# EOS-S3 register map
File version: 0.1
CPU: CM4 r0p1, selectable endian, MPU, FPU, 3 interrupt priority bits
Registers are 32-bit, read-write, reset 0x0 unless marked. A register's access mark holds for its fields unless they carry their own. Offsets are from the block's base; [hi:lo] are bit positions; {n}, {i} and the like mark numbered series; 'fields as' and 'values as' point back to an identical list.

## CRU — Clock Reset Unit
Base 0x40004000
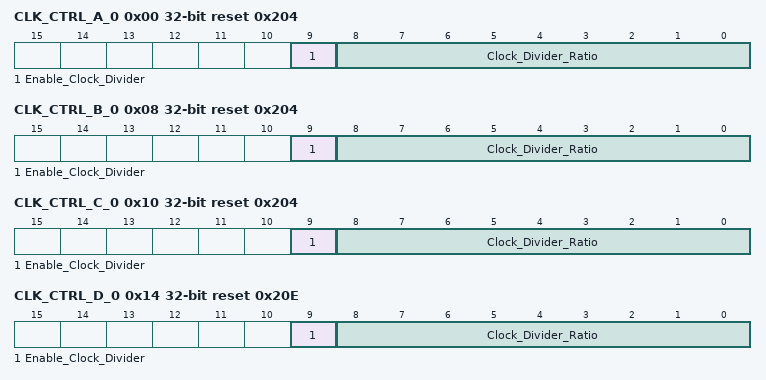
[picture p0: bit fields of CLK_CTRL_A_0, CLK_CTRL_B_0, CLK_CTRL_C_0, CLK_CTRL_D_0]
0x00 CLK_CTRL_A_0 reset 0x204 — For Clock 10 (SYNC Up on A0 and AHB Interface of Batching Memory, AUDIO DMA, M4 SRAMs,M4 Bus Matrix and Trace block)
  [9] Enable_Clock_Divider — Control if the clock divider is on
  [8:0] Clock_Divider_Ratio range 0..510 — High Speed Clock Divider Ratio. Ratio equals value in register + 2. default div is 6
0x04 CLK_CTRL_A_1 — For Clock 10 (SYNC Up on A0 and AHB Interface of Batching Memory, AUDIO DMA, M4 SRAMs,M4 Bus Matrix and Trace block)
  [1:0] Clock_Source_Selection — Select the clock source
    0=with_hs_clk (Selects the High speed/Divided clock); 1=with_32khz_clk (Selects the 32KHz oscillator)
0x08 CLK_CTRL_B_0 reset 0x204 — For Clock 2 (FB, A1 (Including CFGSM))
  fields as CLK_CTRL_A_0
0x0C CLK_CTRL_B_1 — For Clock 2 (FB, A1 (Including CFGSM))
  fields as CLK_CTRL_A_1
0x10 CLK_CTRL_C_0 reset 0x204 — For Clock 8 X4 (FFE X4 clk)
  fields as CLK_CTRL_A_0
0x14 CLK_CTRL_D_0 reset 0x20E — For Clock 11 (To M4 peripherals - AHB/APB bridge, UART, WDT and TIMER)
  [9] Enable_Clock_Divider — Control if the clock divider is on
  [8:0] Clock_Divider_Ratio range 0..510 — High Speed Clock Divider Ratio. Ratio equals value in register + 2, default div is 16
0x18 CLK_CTRL_E_0 — For Clock 12 - Reserved
0x1C CLK_CTRL_E_1 ro — For Clock 12
  [1:0] Clock_Source_Selection — The selected the clock source
    values as CLK_CTRL_A_1.Clock_Source_Selection
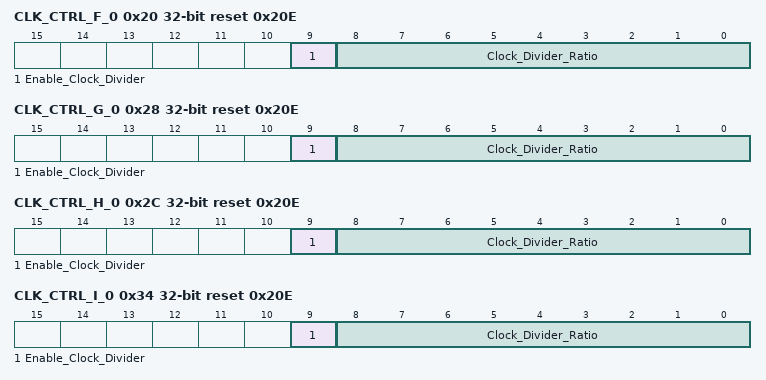
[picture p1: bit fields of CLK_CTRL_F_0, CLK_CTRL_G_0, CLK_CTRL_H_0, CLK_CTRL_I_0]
0x20 CLK_CTRL_F_0 reset 0x20E — For Clock 16 (FB)
  fields as CLK_CTRL_D_0
0x24 CLK_CTRL_F_1 — For Clock 16 (FB)
  fields as CLK_CTRL_A_1
0x28 CLK_CTRL_G_0 reset 0x20E — For Clock 30 (PDM LEFT/RIGHT clk, I2S Master clk)
  [9] Enable_Clock_Divider — Control if the clock divider is on
  [8:0] Clock_Divider_Ratio range 0..510 — High Speed Clock Divider Ratio. Ratio equals value in register + 2, default div is 32
0x2C CLK_CTRL_H_0 reset 0x20E — For Clock 19 (ADC)
  fields as CLK_CTRL_D_0
0x30 CLK_CTRL_H_1 ro — For Clock 19 (ADC)
  fields as CLK_CTRL_A_1
0x34 CLK_CTRL_I_0 reset 0x20E — For Clock 21 (FB - additional clk)
  fields as CLK_CTRL_D_0
0x38 CLK_CTRL_I_1 — For Clock 21 (FB - additional clk)
  fields as CLK_CTRL_A_1
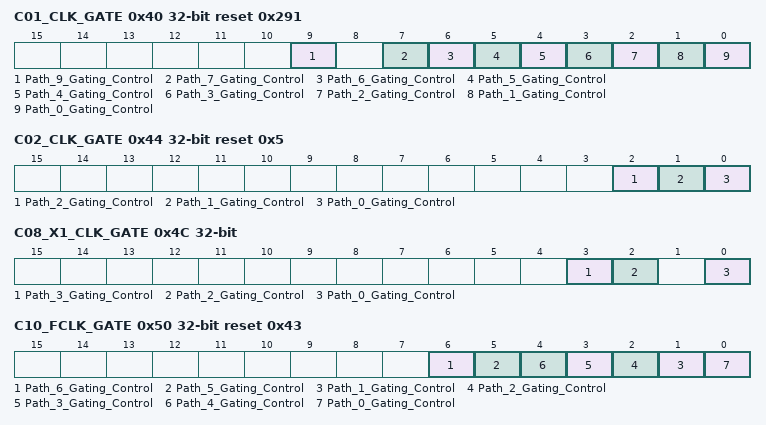
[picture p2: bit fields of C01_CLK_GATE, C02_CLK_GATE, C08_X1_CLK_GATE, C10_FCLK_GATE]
0x40 C01_CLK_GATE reset 0x291 — Gating control for Clock 1
  [all] fields
    0=stop (Clock is stop); 1=run (Clock is runnig)
  [9] Path_9_Gating_Control — For SPT
  [7] Path_7_Gating_Control — Not specified
  [6] Path_6_Gating_Control — To SDMA
  [5] Path_5_Gating_Control — To I2S module inside A1
  [4] Path_4_Gating_Control — To AHB2APB Bridge /CFG DMA Bridge inside A1 , Allow M4 to configure SPI Master to load the code
  [3] Path_3_Gating_Control — To FFE
  [2] Path_2_Gating_Control — To packet FIFO
  [1] Path_1_Gating_Control — To SDMA SRAM
  [0] Path_0_Gating_Control ro — To A0
0x44 C02_CLK_GATE reset 0x5 — Gating control for Clock 2
  [all] fields
    0=stop (Clock is stop); 1=run (Clock is runnig)
  [2] Path_2_Gating_Control — Not specified
  [1] Path_1_Gating_Control — To FB
  [0] Path_0_Gating_Control — To A1 (including CFGSM)
0x48 C08_X4_CLK_GATE — Gating control for FFE X4 clock
  [0] Path_0_Gating_Control — To FFE X4 clk
    0=stop (Clock is stop); 1=run (Clock is runnig)
0x4C C08_X1_CLK_GATE (reset mask 0x7) — Gating control for FFE X1 clock
  [all] fields
    0=stop (Clock is stop); 1=run (Clock is runnig)
  [3] Path_3_Gating_Control — To To PF ASYNC FIFO 0
  [2] Path_2_Gating_Control — To To A0
  [0] Path_0_Gating_Control — To FFE X1 clk
0x50 C10_FCLK_GATE reset 0x43 — Gating control for Clock 10
  [all] fields
    0=stop (Clock is stop); 1=run (Clock is runnig)
  [6] Path_6_Gating_Control — To the SYNC Up on A0 and AHB Interface of Batching Memory
  [5] Path_5_Gating_Control — To AUDIO DMA
  [n] Path_{n}_Gating_Control (n=1..4) — RWHC: To M4 SRAM Instance, M4S{4n-4}~M4S{4n-1}. This bit will be set if any of the Memories (M4S{4n-4}~M4S{4n-1}) been wakeup by Hardware.
  [0] Path_0_Gating_Control ro — To M4 Bus Matrix and Trace block
0x54 C11_CLK_GATE — Gating control for clock 11
  [0] Path_0_Gating_Control — To M4 peripherals - AHB/APB bridge, UART, WDT and TIMER
    0=stop (Clock is stop); 1=run (Clock is runnig)
0x58 C12_CLK_GATE_Reserved ro — Gating control for clock 12
0x5C CS_CLK_GATE — Gating control for SWD CS clock U
  [0] Path_0_Gating_Control — To SWD Clk from PIN
    0=stop (Clock is stop); 1=run (Clock is runnig)
0x60 CU_CLK_GATE_Reserved ro — Not specified
0x64 C16_CLK_GATE — Gating control for FB clock 16
  fields as CS_CLK_GATE
0x68 CLK_RESERVED_0 ro — Not specified
0x6C C19_CLK_GATE — Gating control for ADC clock 19
  [0] Path_0_Gating_Control — To ADC
    0=stop (Clock is stop); 1=run (Clock is runnig)
0x70 C21_CLK_GATE — Gating control for FB additional clock 21
  [0] Path_0_Gating_Control — To FB (additional CLK)
    0=stop (Clock is stop); 1=run (Clock is runnig)
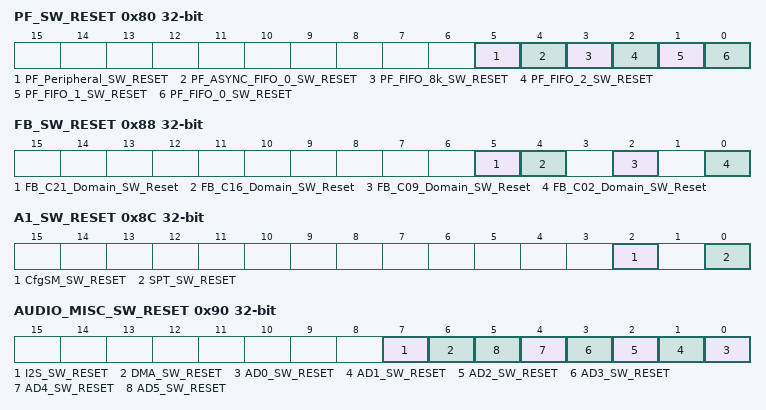
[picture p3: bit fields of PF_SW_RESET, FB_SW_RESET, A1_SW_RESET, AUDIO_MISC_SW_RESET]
0x80 PF_SW_RESET — Packet FIFO power domain Software Reset.Once Program the SW Reset Bit to 1, the corresponding reset will be asserted immediately. Once Program the SW Reset Bit to 0, the corresponding reset will be de-asserted synchronous even the corresponding clock is not running. (Turn off by Clock gating cell)
  [5] PF_Peripheral_SW_RESET — 1'b1 : Enable the Software Reset. FW need to disable it manually.
  [4] PF_ASYNC_FIFO_0_SW_RESET — 1'b1 : Enable the Software Reset. FW need to disable it manually.(R08_P3 as well)
  [3] PF_FIFO_8k_SW_RESET — 1'b1 : Enable the Software Reset. FW need to disable it manually.
  [2] PF_FIFO_2_SW_RESET — 1'b1 : Enable the Software Reset. FW need to disable it manually.
  [1] PF_FIFO_1_SW_RESET — 1'b1 : Enable the Software Reset. FW need to disable it manually.
  [0] PF_FIFO_0_SW_RESET — 1'b1 : Enable the Software Reset. FW need to disable it manually.
0x84 FFE_SW_RESET — Once Program the SW Reset Bit to 1, the corresponding reset will be asserted immediately. Once Program the SW Reset Bit to 0, the corresponding reset will be de-asserted synchronous even the corresponding clock is not running. (Turn off by Clock gating cell)
  [0] FFE_0_X1_SW_Reset — 1'b1 : Enable the Software Reset. FW need to disable it manually. (R01_P3_FFE as well)
  [0] FFE_0_X4_SW_Reset — 1'b1 : Enable the Software Reset. FW need to disable it manually. (R01_P3_FFE as well)
0x88 FB_SW_RESET — Once Program the SW Reset Bit to 1, the corresponding reset will be asserted immediately. Once Program the SW Reset Bit to 0, the corresponding reset will be de-asserted synchronous even the corresponding clock is not running. (Turn off by Clock gating cell)
  [all] fields
    1=Enable the software reset. FW need to disable it manually
  [5] FB_C21_Domain_SW_Reset — 1'b1 : Enable the Software Reset. FW need to disable it manually.
  [4] FB_C16_Domain_SW_Reset — 1'b1 : Enable the Software Reset. FW need to disable it manually.
  [2] FB_C09_Domain_SW_Reset — 1'b1 : Enable the Software Reset. FW need to disable it manually.
  [0] FB_C02_Domain_SW_Reset — 1'b1 : Enable the Software Reset. FW need to disable it manually.
0x8C A1_SW_RESET — Once Program the SW Reset Bit to 1, the corresponding reset will be asserted immediately. Once Program the SW Reset Bit to 0, the corresponding reset will be de-asserted synchronous even the corresponding clock is not running. (Turn off by Clock gating cell)
  [2] CfgSM_SW_RESET — 1'b1 : Enable the Software Reset. FW need to disable it manually. -> This is used to Reset the CfgSM/SPI Master and Related FIFO, DMA and AHB Master
  [0] SPT_SW_RESET — 1'b1 : Enable the Software Reset. FW need to disable it manually. -> This is used to Reset the SPT
0x90 AUDIO_MISC_SW_RESET — Once Program the SW Reset Bit to 1, the corresponding reset will be asserted immediately. Once Program the SW Reset Bit to 0, the corresponding reset will be de-asserted synchronous even the corresponding clock is not running. (Turn off by Clock gating cell)
  [all] fields
    1=Enable the software reset. FW need to disable it manually
  [7] I2S_SW_RESET — 1'b1 : Enable the Software Reset. FW need to disable it manually. ==> For I2S Power Domain. Note: It will only reset the AHB interface R01, but it will not reset R32 path. Suggest to power down, then power on I2S if Software Reset is needed
  [6] DMA_SW_RESET — 1'b1 : Enable the Software Reset. FW need to disable it manually. ==> For DMA Power Domain.
  [n] AD{n}_SW_RESET (n=0..5) — 1'b1 : Enable the Software Reset. FW need to disable it manually. ==> For DMA Power Domain.
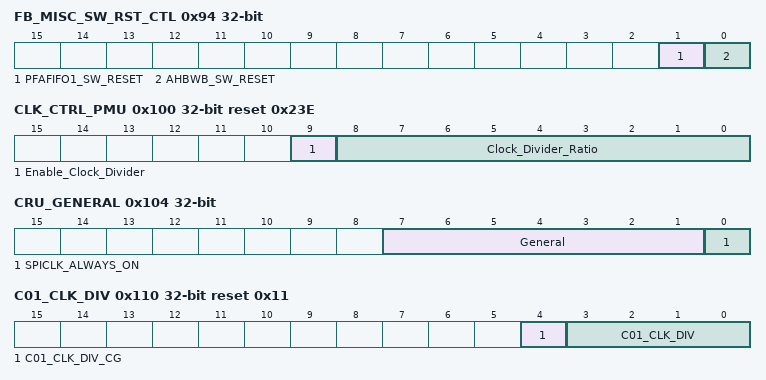
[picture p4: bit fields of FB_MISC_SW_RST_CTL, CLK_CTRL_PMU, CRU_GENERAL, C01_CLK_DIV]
0x94 FB_MISC_SW_RST_CTL — Not specified. FAFIFO1, AHBWB Software Reset control
  [1] PFAFIFO1_SW_RESET — 1'b1 : Enable the Software Reset. FW need to disable it manually. ==> For R41
    1=Enable the software reset. FW need to disable it manually
  [0] AHBWB_SW_RESET — 1'b1 : Enable the Software Reset. FW need to disable it manually. ==> For R40
    1=Enable the software reset. FW need to disable it manually
0x100 CLK_CTRL_PMU reset 0x23E — This Clock is used to delay the Clock gating control signals from PMU. The PMU will monitor the feedback/delayed Clock Gating Control signals to ensure the clocks are OFF before jump to next state. The Firmware needs to Configure this divider to ensure there delay time is longer enough. C23 Clock needs to be 2/3 of the lowest clock frequency of other clocks. For Example, if the Lowest clock frequency of other clocks are 5, then C23 should be lower than 3.33MHz (Or the clock frequency of other clocks should be at least 1.5 times faster than C23.)
  [9] Enable_Clock_Divider — 1'b1 Clock Divider is ON. 1'b0 Clock Divider is OFF, Output the Source Clock Directly
  [8:0] Clock_Divider_Ratio range 0..510 — High Speed Clock Divider Ratio. Ratio is reg value + 2. default div is 64
0x104 CRU_GENERAL — General reg and SPI ALWAYS ON control
  [7:1] General — General purpose register
  [0] SPICLK_ALWAYS_ON — Controls wether the SPI clock is always on or not
    0=always_off (Internal SPI Clock (C00) will be gated off if SPI CS is de-asserted even SPI Clock on the PAD is still running.); 1=always_on (Internal SPIC Clock (C00) is running if SPI Clock on the PAD is toggling regardless of SPI CS value.)
0x108 CRU_DEBUG — CRU Debug registers
  [3:0] CRU_DEBUG_Select — Select the clock to be monitored
    1=monitor_C00_clock (Select clock C00 as the clock to debug); 2=monitor_C01_clock (Select clock C01 as the clock to debug); 3=monitor_C02_clock (Select clock C02 as the clock to debug); 4=monitor_C08X4_clock (Select clock C08X4 as the clock to debug); 5=monitor_C08X1_clock (Select clock C08X1 as the clock to debug); 6=monitor_C09_clock (Select clock C09 as the clock to debug); 7=monitor_C10_clock (Select clock C10 as the clock to debug); 8=monitor_C11_clock (Select clock C11 as the clock to debug); 9=monitor_CS_clock (Select clock CS as the clock to debug); 10=monitor_C16_clock (Select clock C16 as the clock to debug); 11=monitor_C19_clock (Select clock C19 as the clock to debug); 12=monitor_C20_C32_clock (Select clock C20/C32 as the clock to debug); 13=monitor_C21_clock (Select clock C21 as the clock to debug); 14=monitor_C23_clock (Select clock C23 as the clock to debug); 15=monitor_C30_C31_clock (Select clock C30/C31 as the clock to debug)
0x110 C01_CLK_DIV reset 0x11 — Source Clock is C10 (CLK to SDMA,I2S module Inside A1, AHB2APB Bridge /CFG DMA Bridge inside A1 , FFE, Packet FIFO,SDMA,A0 ) If Bit 4 is 0, any change on Bit 3:0 will not take effect. And bit 4 and bit 3:0 can not change at same time.
  [4] C01_CLK_DIV_CG — This bit is used to turn off the clock for the SYNC down Divider
    0=stop (Clock is stop); 1=run (Clock is runnig)
  [3:0] C01_CLK_DIV — The input clock frequency will be divided and generate the corresponding clock output. div is reg value + 1
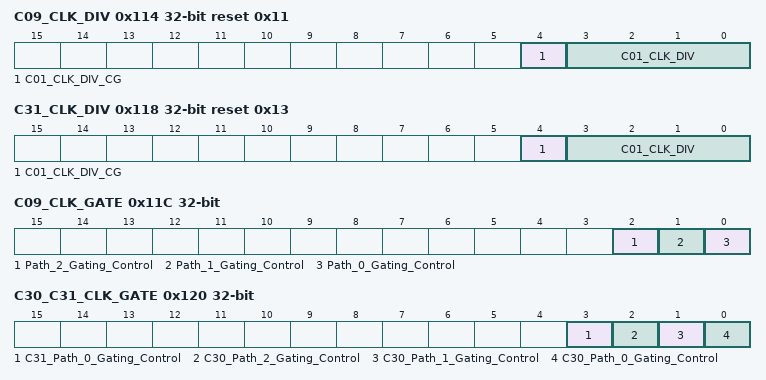
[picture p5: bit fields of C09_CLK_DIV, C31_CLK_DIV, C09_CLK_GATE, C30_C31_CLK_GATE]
0x114 C09_CLK_DIV reset 0x11 — Source Clock is C10 (CLK to Voice APB interface, PIF, FB). If Bit 4 is 0, any change on Bit 3:0 will not take effect. And bit 4 and bit 3:0 can not change at same time.
  fields as C01_CLK_DIV
0x118 C31_CLK_DIV reset 0x13 — Source Clock is C30 (LPSD CLK).If Bit 4 is 0, any change on Bit 3:0 will not take effect. And bit 4 and bit 3:0 can not change at same time.
  fields as C01_CLK_DIV
0x11C C09_CLK_GATE — Gating control for clock 09
  [all] fields
    0=stop (Clock is stop); 1=run (Clock is runnig)
  [2] Path_2_Gating_Control — To FB
  [1] Path_1_Gating_Control — To PIF
  [0] Path_0_Gating_Control — To voice APB interface
0x120 C30_C31_CLK_GATE — Gating control for clocks 30-31
  [all] fields
    0=stop (Clock is stop); 1=run (Clock is runnig)
  [3] C31_Path_0_Gating_Control — To LPSD clk
  [2] C30_Path_2_Gating_Control — To I2S Master Clk
  [1] C30_Path_1_Gating_Control — To PDM RIGHT CLK
  [0] C30_Path_0_Gating_Control — To PDM LEFT CLK
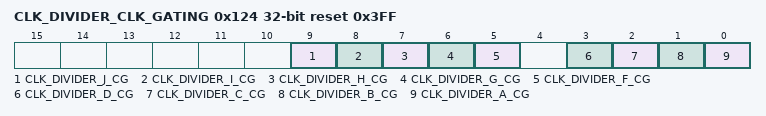
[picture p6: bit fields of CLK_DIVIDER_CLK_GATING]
0x124 CLK_DIVIDER_CLK_GATING reset 0x3FF — Control for divider gates in different clocks
  [all] fields
    0=stop (Clock is stop); 1=run (Clock is runnig)
  [9] CLK_DIVIDER_J_CG — To C23 (PMU clk gating control)
  [8] CLK_DIVIDER_I_CG — To C21 (FB)
  [7] CLK_DIVIDER_H_CG — To C19 (ADC)<F11>
  [6] CLK_DIVIDER_G_CG — To C30, C31 (PDM LEFT/RIGHT Clk, I2S_MASTER clk, LPSD CLK)
  [5] CLK_DIVIDER_F_CG — To C16 (FB)
  [3] CLK_DIVIDER_D_CG — To C11 (M4 peripherals - AHB/APB bridge, UART, WDT and TIMER)
  [2] CLK_DIVIDER_C_CG — To C08 (FFE X4, X1)
  [1] CLK_DIVIDER_B_CG — To C02 (FB, A1 (Including CFGSM))
  [0] CLK_DIVIDER_A_CG — To C10,C01,C09 (SYNC Up on A0, AHB Interface of Batching Memory, AUDIO DMA, M4 SRAMs,M4 Bus Matrix , M4 Trace block, Debug controller, SDMA,I2S module Inside A1, AHB2APB Bridge /CFG DMA Bridge inside A1 , FFE, Packet FIFO,SDMA,A0, Voice APB interface, PIF, FB). Note: Firmware Should NOT program this bit to 0.
0x130 CLK_SWITCH_FOR_B — For Clock 2 (FB, A1 (Including CFGSM))
  [0] Clock_Source_Selection — Choose between High Speed Clock or 32Khz oscillator
    values as CLK_CTRL_A_1.Clock_Source_Selection
0x134 CLK_SWITCH_FOR_C — For Clock 8 X4 (FFE X4 clk)
  fields as CLK_SWITCH_FOR_B
0x138 CLK_SWITCH_FOR_D — For Clock 11 (To M4 peripherals - AHB/APB bridge, UART, WDT and TIMER)
  fields as CLK_SWITCH_FOR_B
0x13C CLK_SWITCH_FOR_H — For Clock 19 (ADC)
  fields as CLK_SWITCH_FOR_B
0x140 CLK_SWITCH_FOR_J — For CLK 23 (PMU clk gating control)
  fields as CLK_SWITCH_FOR_B
0x144 CLK_SWITCH_FOR_G — To C30(PDM LEFT/RIGHT Clk, I2S_MASTER)
  fields as CLK_SWITCH_FOR_B
